# CY8C5268LTI_LP030 register map
File version: 0.1
CY8C52LP
Registers are 8-bit, read-write, no defined reset value unless marked. A register's access mark holds for its fields unless they carry their own. Offsets are from the block's base; lines under a group give offsets from that group; [hi:lo] are bit positions; {n}, {i} and the like mark numbered series; 'fields as' and 'values as' point back to an identical list; <NAME> marks a mode.

## Memory map
0x400043A3 Tamper_Timer size 0xB64
0x400043A3 UART_TIMER size 0xB70
0x400049C8 EZI2Cs size 0x11
0x40006423 UART_1 size 0x43 — UART
0x40006462 UART_OSDP size 0x103 — UART
0x40006472 OptSelect size 0x1

## OptSelect
Base 0x40006472
0x00 OptSelect_CONTROL_REG

## Tamper_Timer
Base 0x400043A3
0x00 Tamper_Timer_GLOBAL_ENABLE — PM.ACT.CFG
  [3:0] en_timer — Enable timer/counters.
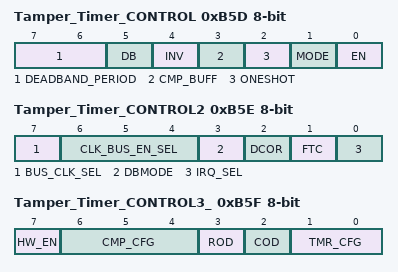
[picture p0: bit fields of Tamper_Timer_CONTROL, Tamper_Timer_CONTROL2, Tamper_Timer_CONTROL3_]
0xB5D Tamper_Timer_CONTROL — TMRx.CFG0
  [7:6] DEADBAND_PERIOD
  [5] DB — Deadband mode--Deadband phases phi1 and phi2 are outputted on CMP and TC output pins respectively.
    0=Timer (CMP and TC are output.); 1=Deadband (PHI1 (instead of CMP) and PHI2 (instead of TC) are output.)
  [4] INV — Invert sense of TIMEREN signal
  [3] CMP_BUFF — Buffer compare register. Compare register updates only on timer terminal count.
  [2] ONESHOT — Timer stops upon reaching stop condition defined by TMR_CFG bits. Can be restarted by asserting TIMER RESET or disabling and re-enabling block.
  [1] MODE — Mode. (0 = Timer; 1 = Comparator)
    0=Timer mode. CNT/CMP register holds timer count value.; 1=Comparator mode. CNT/CMP register holds comparator threshold value.
  [0] EN — Enables timer/comparator.
0xB5E Tamper_Timer_CONTROL2 — TMRx.CFG1
  [7] BUS_CLK_SEL — Bus Clock selection.
  [6:4] CLK_BUS_EN_SEL — Digital Global Clock selection.
  [3] DBMODE — Deadband mode (asynchronous/synchronous). CMP output pin is also affected when not in deadband mode (CFG0.DEADBAND).
  [2] DCOR — Disable Clear on Read (DCOR) of Status Register SR0.
  [1] FTC — First Terminal Count (FTC). Setting this bit forces a single pulse on the TC pin when first enabled.
    0=Disable_FTC (Disable the single cycle pulse, which signifies the timer is starting.); 1=Enable_FTC (Enable the single cycle pulse, which signifies the timer is starting.)
  [0] IRQ_SEL — Irq selection. (0 = raw interrupts; 1 = status register interrupts)
0xB5F Tamper_Timer_CONTROL3_ — TMRx.CFG2
  [7] HW_EN — When set Timer Enable controls counting.
  [6:4] CMP_CFG — Comparator configurations
    0=Equal (Compare Equal); 1=Less_than (Compare Less Than); 2=Less_than_or_equal (Compare Less Than or Equal .); 3=Greater (Compare Greater Than .); 4=Greater_than_or_equal (Compare Greater Than or Equal)
  [3] ROD — Reset On Disable (ROD). Resets internal state of output logic
  [2] COD — Clear On Disable (COD). Clears or gates outputs to zero.
  [1:0] TMR_CFG — Timer configuration (MODE = 0): 000 = Continuous; 001 = Pulsewidth; 010 = Period; 011 = Stop on IRQ
    0=Continuous (Timer runs while EN bit of CFG0 register is set to '1'.); 1=Pulsewidth (Timer runs from positive to negative edge of TIMEREN.); 2=Period (Timer runs from positive to positive edge of TIMEREN.); 3=Irq (Timer runs until IRQ.)
0xB61 Tamper_Timer_PERIOD 16-bit — TMRx.PER0 - Assigned Period
0xB63 Tamper_Timer_COUNTER 16-bit — TMRx.CNT_CMP0 - Current Down Counter Value

## UART_OSDP — UART
Base 0x40006462
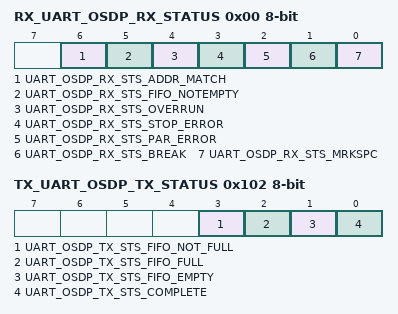
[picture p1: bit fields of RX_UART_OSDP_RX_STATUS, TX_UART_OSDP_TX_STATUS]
0x00 RX_UART_OSDP_RX_STATUS — RX status register
  [6] UART_OSDP_RX_STS_ADDR_MATCH ro, [5] UART_OSDP_RX_STS_FIFO_NOTEMPTY ro, [4] UART_OSDP_RX_STS_OVERRUN ro, [3] UART_OSDP_RX_STS_STOP_ERROR ro, [2] UART_OSDP_RX_STS_PAR_ERROR ro, [1] UART_OSDP_RX_STS_BREAK ro, [0] UART_OSDP_RX_STS_MRKSPC ro
0xC3 RX_UART_OSDP_RX_ADDRESS1 — RX Address1 Register
0xD3 RX_UART_OSDP_RX_ADDRESS2 — RX Address2 Register
0xE3 RX_UART_OSDP_RX_DATA — RX Data Register
0xE5 TX_UART_OSDP_TX_DATA — TX Data Register
0x102 TX_UART_OSDP_TX_STATUS — TX status register
  [3] UART_OSDP_TX_STS_FIFO_NOT_FULL ro, [2] UART_OSDP_TX_STS_FIFO_FULL ro, [1] UART_OSDP_TX_STS_FIFO_EMPTY ro, [0] UART_OSDP_TX_STS_COMPLETE ro
